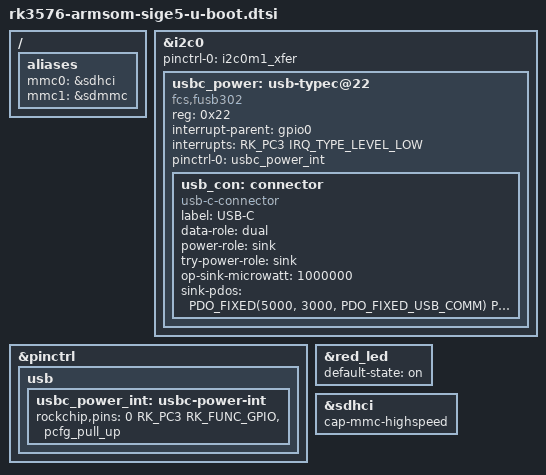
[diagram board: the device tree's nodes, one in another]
// SPDX-License-Identifier: (GPL-2.0+ OR MIT)

#include <dt-bindings/usb/pd.h>
#include "rk3576-u-boot.dtsi"

/ {
	aliases {
		mmc0 = &sdhci;
		mmc1 = &sdmmc;
	};
};

&i2c0 {
	pinctrl-0 = <&i2c0m1_xfer>;
	pinctrl-names = "default";

	status = "okay";

	usbc_power: usb-typec@22 {
		compatible = "fcs,fusb302";
		reg = <0x22>;
		interrupt-parent = <&gpio0>;
		interrupts = <RK_PC3 IRQ_TYPE_LEVEL_LOW>;
		pinctrl-0 = <&usbc_power_int>;
		pinctrl-names = "default";
		status = "okay";

		usb_con: connector {
			compatible = "usb-c-connector";
			label = "USB-C";
			data-role = "dual";
			power-role = "sink";
			try-power-role = "sink";
			op-sink-microwatt = <1000000>;
			sink-pdos = <
				PDO_FIXED(5000, 3000, PDO_FIXED_USB_COMM)
				PDO_FIXED(9000, 3000, PDO_FIXED_USB_COMM)
				PDO_FIXED(12000, 3000, PDO_FIXED_USB_COMM)
			>;
		};
	};
};

&pinctrl {
	usb {
		usbc_power_int: usbc-power-int {
			rockchip,pins = <0 RK_PC3 RK_FUNC_GPIO &pcfg_pull_up>;
		};
	};
};

&red_led {
	default-state = "on";
};

&sdhci {
	cap-mmc-highspeed;
};
